# XMC4100 register map
Vendor: Infineon; File version: 1.5.2 (Reference Manual v1.5)
CPU: CM4 r2p0, little endian, MPU, FPU, 6 interrupt priority bits
Registers are 32-bit, read-write, reset 0x0 unless marked. A register's access mark holds for its fields unless they carry their own. Offsets are from the block's base; [hi:lo] are bit positions; {n}, {i} and the like mark numbered series.

## SCU_INTERRUPT — System Control Unit
Base 0x50004074
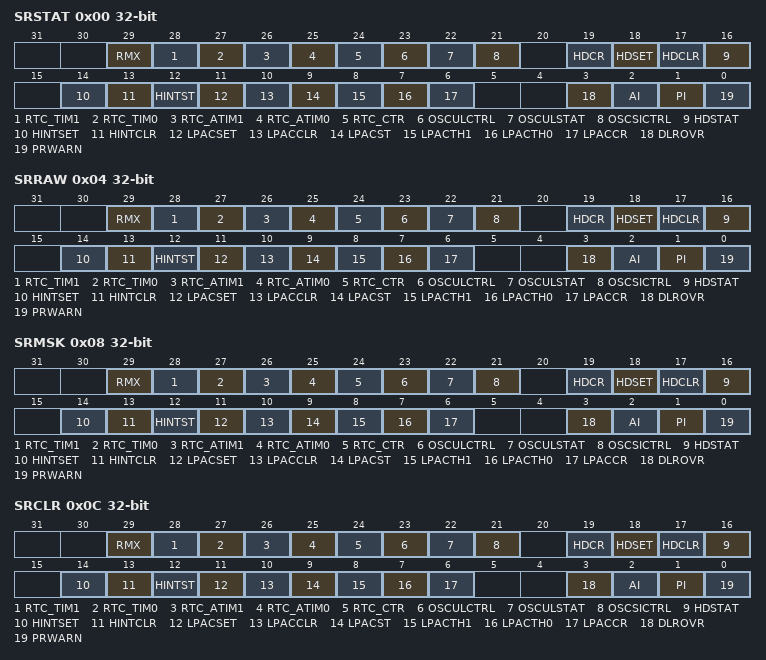
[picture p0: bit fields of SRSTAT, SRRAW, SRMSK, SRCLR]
0x00 SRSTAT ro — SCU Service Request Status
  [29] RMX — Retention Memory Mirror Register Update Status
    0=Not updated; 1=Update completed
  [28] RTC_TIM1 — RTC TIM1 Mirror Register Update Status
    0=Not updated; 1=Update completed
  [27] RTC_TIM0 — RTC TIM0 Mirror Register Update Status
    0=Not updated; 1=Update completed
  [26] RTC_ATIM1 — RTC ATIM1 Mirror Register Update Status
    0=Not updated; 1=Update completed
  [25] RTC_ATIM0 — RTC ATIM0 Mirror Register Update Status
    0=Not updated; 1=Update completed
  [24] RTC_CTR — RTC CTR Mirror Register Update Status
    0=Not updated; 1=Update completed
  [23] OSCULCTRL — OSCULCTRL Mirror Register Update Status
    0=Not updated; 1=Update completed
  [22] OSCULSTAT — OSCULSTAT Mirror Register Update Status
    0=Not updated; 1=Update completed
  [21] OSCSICTRL — OSCSICTRL Mirror Register Update Status
    0=Not updated; 1=Update completed
  [19] HDCR — HDCR Mirror Register Update Status
    0=Not updated; 1=Update completed
  [18] HDSET — HDSET Mirror Register Update Status
    0=Not updated; 1=Update completed
  [17] HDCLR — HDCLR Mirror Register Update Status
    0=Not updated; 1=Update completed
  [16] HDSTAT — HDSTAT Mirror Register Update Status
    0=Not updated; 1=Update completed
  [14] HINTSET — HINTSET Mirror Register Update Status
    0=Not updated; 1=Update completed
  [13] HINTCLR — HINTCLR Mirror Register Update Status
    0=Not updated; 1=Update completed
  [12] HINTST — HINTST Mirror Register Update Status
    0=Not updated; 1=Update completed
  [11] LPACSET — LPACSET Mirror Register Update Status
    0=Not updated; 1=Update completed
  [10] LPACCLR — LPACCLR Mirror Register Update Status
    0=Not updated; 1=Update completed
  [9] LPACST — LPACST Mirror Register Update Status
    0=Not updated; 1=Update completed
  [8] LPACTH1 — LPACTH1 Mirror Register Update Status
    0=Not updated; 1=Update completed
  [7] LPACTH0 — LPACTH0 Mirror Register Update Status
    0=Not updated; 1=Update completed
  [6] LPACCR — LPACLR Mirror Register Update Status
    0=Not updated; 1=Update completed
  [3] DLROVR — DLR Request Overrun Interrupt Status
  [2] AI — Alarm Interrupt Status
  [1] PI — RTC Periodic Interrupt Status
  [0] PRWARN — WDT pre-warning Interrupt Status
    0=Inactive; 1=Active
0x04 SRRAW ro — SCU Raw Service Request Status
  [29] RMX — Retention Memory Mirror Register Update Status Before Masking
    0=Not updated; 1=Update completed
  [28] RTC_TIM1 — RTC TIM1 Mirror Register Update Status Before Masking
    0=Not updated; 1=Update completed
  [27] RTC_TIM0 — RTC TIM0 Mirror Register Update Before Masking Status
    0=Not updated; 1=Update completed
  [26] RTC_ATIM1 — RTC ATIM1 Mirror Register Update Status Before Masking
    0=Not updated; 1=Update completed
  [25] RTC_ATIM0 — RTC ATIM0 Mirror Register Update Status Before Masking
    0=Not updated; 1=Update completed
  [24] RTC_CTR — RTC CTR Mirror Register Update Status Before Masking
    0=Not updated; 1=Update completed
  [23] OSCULCTRL — OSCULCTRL Mirror Register Update Status Before Masking
    0=Not updated; 1=Update completed
  [22] OSCULSTAT — OSCULSTAT Mirror Register Update Status Before Masking
    0=Not updated; 1=Update completed
  [21] OSCSICTRL — OSCSICTRL Mirror Register Update Status Before Masking
    0=Not updated; 1=Update completed
  [19] HDCR — HDCR Mirror Register Update Status Before Masking
    0=Not updated; 1=Update completed
  [18] HDSET — HDSET Mirror Register Update Status Before Masking
    0=Not updated; 1=Update completed
  [17] HDCLR — HDCLR Mirror Register Update Status Before Masking
    0=Not updated; 1=Update completed
  [16] HDSTAT — HDSTAT Mirror Register Update Status Before Masking
    0=Not updated; 1=Update completed
  [14] HINTSET — HINTSET Mirror Register Update Status Before Masking
    0=Not updated; 1=Update completed
  [13] HINTCLR — HINTCLR Mirror Register Update Status Before Masking
    0=Not updated; 1=Update completed
  [12] HINTST — HINTST Mirror Register Update Status Before Masking
    0=Not updated; 1=Update completed
  [11] LPACSET — LPACSET Mirror Register Update Status Before Masking
    0=Not updated; 1=Update completed
  [10] LPACCLR — LPACCLR Mirror Register Update Status Before Masking
    0=Not updated; 1=Update completed
  [9] LPACST — LPACST Mirror Register Update Status Before Masking
    0=Not updated; 1=Update completed
  [8] LPACTH1 — LPACTH1 Mirror Register Update Status Before Masking
    0=Not updated; 1=Update completed
  [7] LPACTH0 — LPACTH0 Mirror Register Update Status Before Masking
    0=Not updated; 1=Update completed
  [6] LPACCR — LPACLR Mirror Register Update Status Before Masking
    0=Not updated; 1=Update completed
  [3] DLROVR — DLR Request Overrun Interrupt Status Before Masking
  [2] AI — RTC Raw Alarm Interrupt Status Before Masking
  [1] PI — RTC Raw Periodic Interrupt Status Before Masking
  [0] PRWARN — WDT pre-warning Interrupt Status Before Masking
    0=Inactive; 1=Active
0x08 SRMSK — SCU Service Request Mask
  [all] fields
    0=Disabled; 1=Enabled
  [29] RMX — Retention Memory Mirror Register Update Mask
  [28] RTC_TIM1 — RTC TIM1 Mirror Register Update Mask
  [27] RTC_TIM0 — RTC TIM0 Mirror Register Update Mask
  [26] RTC_ATIM1 — RTC ATIM1 Mirror Register Update Mask
  [25] RTC_ATIM0 — RTC ATIM0 Mirror Register Update Mask
  [24] RTC_CTR — RTC CTR Mirror Register Update Mask
  [23] OSCULCTRL — OSCULCTRL Mirror Register Update Mask
  [22] OSCULSTAT — OSCULSTAT Mirror Register Update Mask
  [21] OSCSICTRL — OSCSICTRL Mirror Register Update Mask
  [19] HDCR — HDCR Mirror Register Update Mask
  [18] HDSET — HDSET Mirror Register Update Mask
  [17] HDCLR — HDCLR Mirror Register Update Mask
  [16] HDSTAT — HDSTAT Mirror Register Update Mask
  [14] HINTSET — HINTSET Mirror Register Update Interrupt Mask
  [13] HINTCLR — HINTCLR Mirror Register Update Interrupt Mask
  [12] HINTST — HINTST Mirror Register Update Interrupt Mask
  [11] LPACSET — LPACSET Mirror Register Update Interrupt Mask
  [10] LPACCLR — LPACCLR Mirror Register Update Interrupt Mask
  [9] LPACST — LPACST Mirror Register Update Interrupt Mask
  [8] LPACTH1 — LPACTH1 Mirror Register Update Interrupt Mask
  [7] LPACTH0 — LPACTH0 Mirror Register Update Interrupt Mask
  [6] LPACCR — LPACLR Mirror Register Update Interrupt Mask
  [3] DLROVR — DLR Request Overrun Interrupt Mask
  [2] AI — RTC Alarm Interrupt Mask
  [1] PI — RTC Periodic Interrupt Mask
  [0] PRWARN — WDT pre-warning Interrupt Mask
0x0C SRCLR wo — SCU Service Request Clear
  [all] fields
    0=No effect; 1=Clear the status bit
  [29] RMX — Retention Memory Mirror Register Update Clear
  [28] RTC_TIM1 — RTC TIM1 Mirror Register Update Clear
  [27] RTC_TIM0 — RTC TIM0 Mirror Register Update Clear
  [26] RTC_ATIM1 — RTC ATIM1 Mirror Register Update Clear
  [25] RTC_ATIM0 — RTC ATIM0 Mirror Register Update Clear
  [24] RTC_CTR — RTC CTR Mirror Register Update Clear
  [23] OSCULCTRL — OSCULCTRL Mirror Register Update Clear
  [22] OSCULSTAT — OSCULSTAT Mirror Register Update Clear
  [21] OSCSICTRL — OSCSICTRL Mirror Register Update Clear
  [19] HDCR — HDCR Mirror Register Update Clear
  [18] HDSET — HDSET Mirror Register Update Clear
  [17] HDCLR — HDCLR Mirror Register Update Clear
  [16] HDSTAT — HDCTAT Mirror Register Update Clear
  [14] HINTSET — HINTSET Mirror Register Update Interrupt Clear
  [13] HINTCLR — HINTCLR Mirror Register Update Interrupt Clear
  [12] HINTST — HINTST Mirror Register Update Interrupt Clear
  [11] LPACSET — LPACSET Mirror Register Update Interrupt Clear
  [10] LPACCLR — LPACCLR Mirror Register Update Interrupt Clear
  [9] LPACST — LPACST Mirror Register Update Interrupt Clear
  [8] LPACTH1 — LPACTH1 Mirror Register Update Interrupt Clear
  [7] LPACTH0 — LPACTH0 Mirror Register Update Interrupt Clear
  [6] LPACCR — LPACLR Mirror Register Update Interrupt Clear
  [3] DLROVR — DLR Request Overrun Interrupt clear
  [2] AI — RTC Alarm Interrupt Clear
  [1] PI — RTC Periodic Interrupt Clear
  [0] PRWARN — WDT pre-warning Interrupt Clear
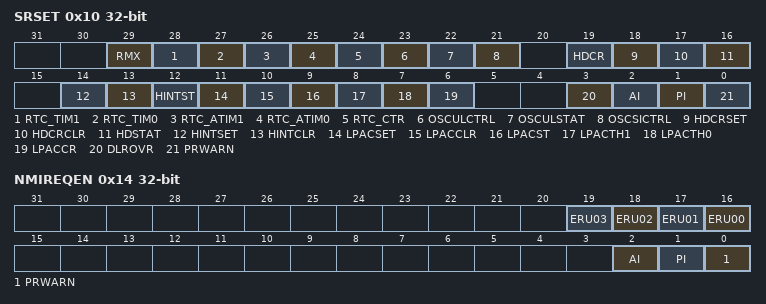
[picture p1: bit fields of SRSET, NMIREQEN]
0x10 SRSET wo — SCU Service Request Set
  [all] fields
    0=No effect; 1=set the status bit
  [29] RMX — Retention Memory Mirror Register Update Set
  [28] RTC_TIM1 — RTC TIM1 Mirror Register Update Set
  [27] RTC_TIM0 — RTC TIM0 Mirror Register Update Set
  [26] RTC_ATIM1 — RTC ATIM1 Mirror Register Update Set
  [25] RTC_ATIM0 — RTC ATIM0 Mirror Register Update Set
  [24] RTC_CTR — RTC CTR Mirror Register Update Set
  [23] OSCULCTRL — OSCULCTRL Mirror Register Update Set
  [22] OSCULSTAT — OSCULSTAT Mirror Register Update Set
  [21] OSCSICTRL — OSCSICTRL Mirror Register Update Set
  [19] HDCR — HDCR Mirror Register Update Set
  [18] HDCRSET — HDCRSET Mirror Register Update Set
  [17] HDCRCLR — HDCRCLR Mirror Register Update Set
  [16] HDSTAT — HDSTAT Mirror Register Update Set
  [14] HINTSET — HINTSET Mirror Register Update Interrupt Set
  [13] HINTCLR — HINTCLR Mirror Register Update Interrupt Set
  [12] HINTST — HINTST Mirror Register Update Interrupt Set
  [11] LPACSET — LPACSET Mirror Register Update Interrupt Set
  [10] LPACCLR — LPACCLR Mirror Register Update Interrupt Set
  [9] LPACST — LPACST Mirror Register Update Interrupt Set
  [8] LPACTH1 — LPACTH1 Mirror Register Update Interrupt Set
  [7] LPACTH0 — LPACTH0 Mirror Register Update Interrupt Set
  [6] LPACCR — LPACLR Mirror Register Update Interrupt Set
  [3] DLROVR — DLR Request Overrun Interrupt Set
  [2] AI — RTC Alarm Interrupt Set
  [1] PI — RTC Periodic Interrupt Set
  [0] PRWARN — WDT pre-warning Interrupt Set
0x14 NMIREQEN — SCU Service Request Mask
  [all] fields
    0=Disabled; 1=Enabled
  [n+16] ERU{n:02} (n=0..3) — Promote Channel {n} Interrupt of ERU0 Request to NMI Request
  [2] AI — Promote RTC Alarm Interrupt Request to NMI Request
  [1] PI — Promote RTC Periodic Interrupt request to NMI Request
  [0] PRWARN — Promote Pre-Warning Interrupt Request to NMI Request

## Notices in the file
Copyright (C) 2016 Infineon Technologies AG. All rights reserved.
Infineon Technologies AG (Infineon) is supplying this software for use with
Infineon's microcontrollers.  This file can be freely distributed within
development tools that are supporting such microcontrollers.
THIS SOFTWARE IS PROVIDED "AS IS".  NO WARRANTIES, WHETHER EXPRESS, IMPLIED
OR STATUTORY, INCLUDING, BUT NOT LIMITED TO, IMPLIED WARRANTIES OF
MERCHANTABILITY AND FITNESS FOR A PARTICULAR PURPOSE APPLY TO THIS SOFTWARE.
INFINEON SHALL NOT, IN ANY CIRCUMSTANCES, BE LIABLE FOR SPECIAL, INCIDENTAL,
OR CONSEQUENTIAL DAMAGES, FOR ANY REASON WHATSOEVER.
